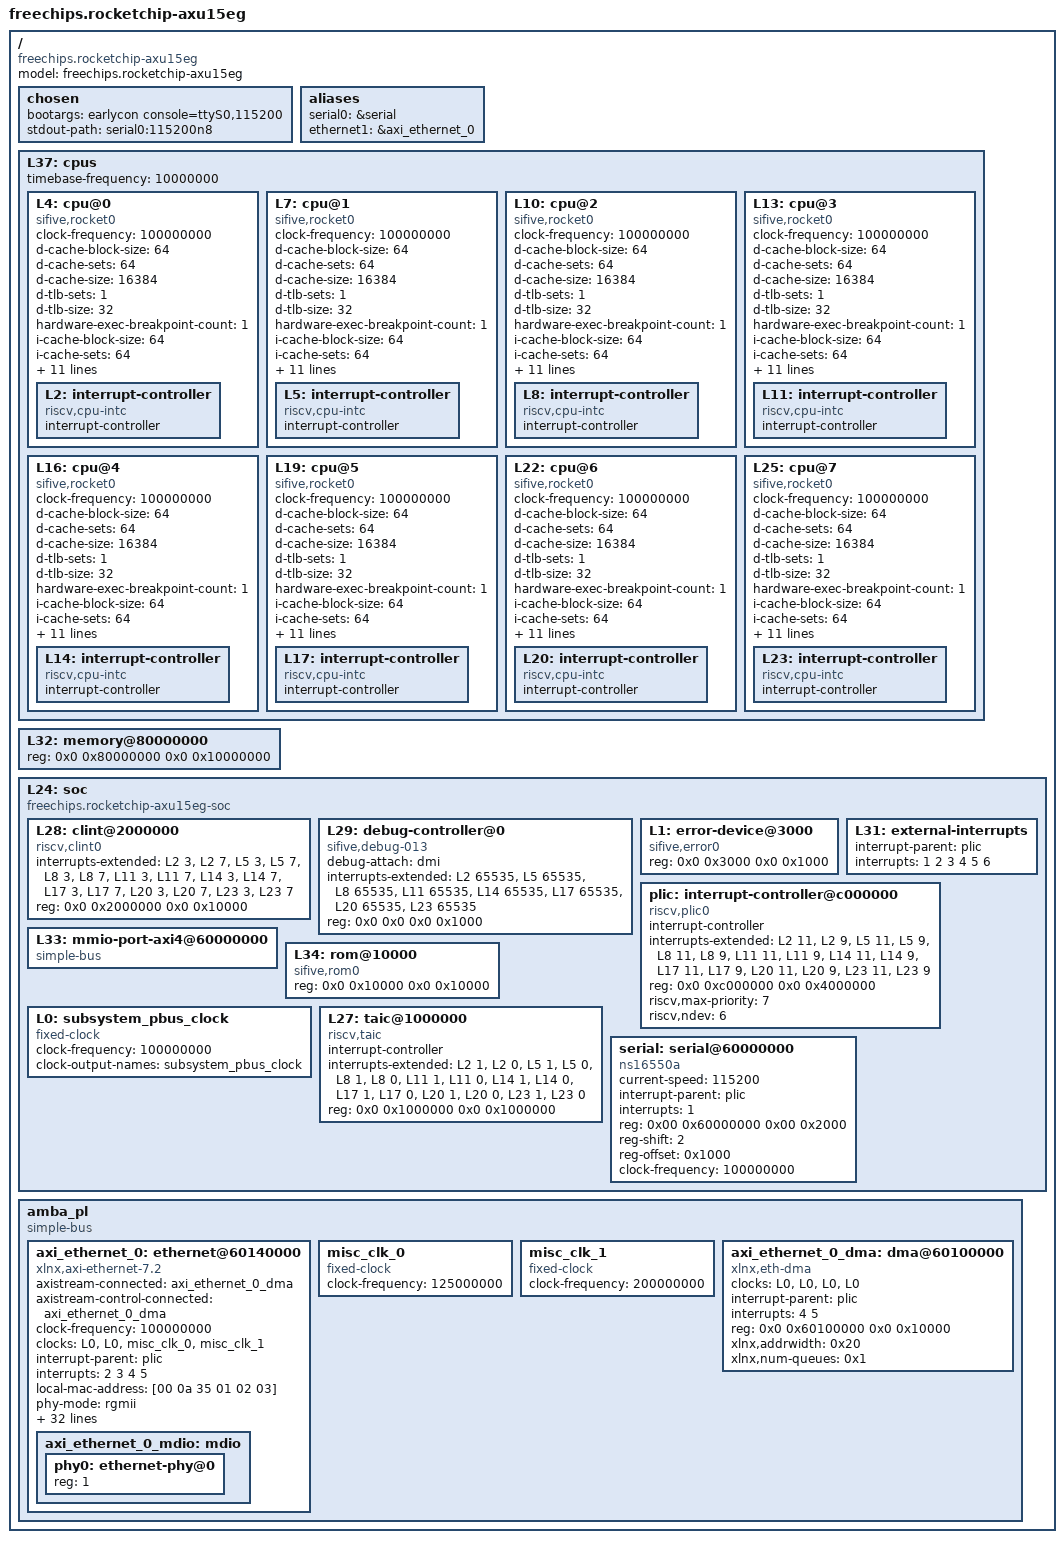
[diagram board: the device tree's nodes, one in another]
/dts-v1/;

/ {
        #address-cells = <2>;
        #size-cells = <2>;
        compatible = "freechips.rocketchip-axu15eg";
        model = "freechips.rocketchip-axu15eg";

        chosen {
            bootargs = "earlycon console=ttyS0,115200";
            stdout-path = "serial0:115200n8";
        };

        aliases {
            serial0 = &serial;
            ethernet1 = &axi_ethernet_0;
        };

        L37: cpus {
                #address-cells = <1>;
                #size-cells = <0>;
                timebase-frequency = <10000000>;
                L4: cpu@0 {
                        clock-frequency = <100000000>;
                        compatible = "sifive,rocket0", "riscv";
                        d-cache-block-size = <64>;
                        d-cache-sets = <64>;
                        d-cache-size = <16384>;
                        d-tlb-sets = <1>;
                        d-tlb-size = <32>;
                        device_type = "cpu";
                        hardware-exec-breakpoint-count = <1>;
                        i-cache-block-size = <64>;
                        i-cache-sets = <64>;
                        i-cache-size = <16384>;
                        i-tlb-sets = <1>;
                        i-tlb-size = <32>;
                        mmu-type = "riscv,sv39";
                        next-level-cache = <&L32>;
                        reg = <0x0>;
                        riscv,isa = "rv64imafdc";
                        riscv,pmpgranularity = <4>;
                        riscv,pmpregions = <8>;
                        status = "okay";
                        timebase-frequency = <10000000>;
                        tlb-split;
                        L2: interrupt-controller {
                                #address-cells = <1>;
                                #interrupt-cells = <1>;
                                compatible = "riscv,cpu-intc";
                                interrupt-controller;
                        };
                };
                L7: cpu@1 {
                        clock-frequency = <100000000>;
                        compatible = "sifive,rocket0", "riscv";
                        d-cache-block-size = <64>;
                        d-cache-sets = <64>;
                        d-cache-size = <16384>;
                        d-tlb-sets = <1>;
                        d-tlb-size = <32>;
                        device_type = "cpu";
                        hardware-exec-breakpoint-count = <1>;
                        i-cache-block-size = <64>;
                        i-cache-sets = <64>;
                        i-cache-size = <16384>;
                        i-tlb-sets = <1>;
                        i-tlb-size = <32>;
                        mmu-type = "riscv,sv39";
                        next-level-cache = <&L32>;
                        reg = <0x1>;
                        riscv,isa = "rv64imafdc";
                        riscv,pmpgranularity = <4>;
                        riscv,pmpregions = <8>;
                        status = "okay";
                        timebase-frequency = <10000000>;
                        tlb-split;
                        L5: interrupt-controller {
                                #address-cells = <1>;
                                #interrupt-cells = <1>;
                                compatible = "riscv,cpu-intc";
                                interrupt-controller;
                        };
                };
                L10: cpu@2 {
                        clock-frequency = <100000000>;
                        compatible = "sifive,rocket0", "riscv";
                        d-cache-block-size = <64>;
                        d-cache-sets = <64>;
                        d-cache-size = <16384>;
                        d-tlb-sets = <1>;
                        d-tlb-size = <32>;
                        device_type = "cpu";
                        hardware-exec-breakpoint-count = <1>;
                        i-cache-block-size = <64>;
                        i-cache-sets = <64>;
                        i-cache-size = <16384>;
                        i-tlb-sets = <1>;
                        i-tlb-size = <32>;
                        mmu-type = "riscv,sv39";
                        next-level-cache = <&L32>;
                        reg = <0x2>;
                        riscv,isa = "rv64imafdc";
                        riscv,pmpgranularity = <4>;
                        riscv,pmpregions = <8>;
                        status = "okay";
                        timebase-frequency = <10000000>;
                        tlb-split;
                        L8: interrupt-controller {
                                #address-cells = <1>;
                                #interrupt-cells = <1>;
                                compatible = "riscv,cpu-intc";
                                interrupt-controller;
                        };
                };
                L13: cpu@3 {
                        clock-frequency = <100000000>;
                        compatible = "sifive,rocket0", "riscv";
                        d-cache-block-size = <64>;
                        d-cache-sets = <64>;
                        d-cache-size = <16384>;
                        d-tlb-sets = <1>;
                        d-tlb-size = <32>;
                        device_type = "cpu";
                        hardware-exec-breakpoint-count = <1>;
                        i-cache-block-size = <64>;
                        i-cache-sets = <64>;
                        i-cache-size = <16384>;
                        i-tlb-sets = <1>;
                        i-tlb-size = <32>;
                        mmu-type = "riscv,sv39";
                        next-level-cache = <&L32>;
                        reg = <0x3>;
                        riscv,isa = "rv64imafdc";
                        riscv,pmpgranularity = <4>;
                        riscv,pmpregions = <8>;
                        status = "okay";
                        timebase-frequency = <10000000>;
                        tlb-split;
                        L11: interrupt-controller {
                                #address-cells = <1>;
                                #interrupt-cells = <1>;
                                compatible = "riscv,cpu-intc";
                                interrupt-controller;
                        };
                };
                L16: cpu@4 {
                        clock-frequency = <100000000>;
                        compatible = "sifive,rocket0", "riscv";
                        d-cache-block-size = <64>;
                        d-cache-sets = <64>;
                        d-cache-size = <16384>;
                        d-tlb-sets = <1>;
                        d-tlb-size = <32>;
                        device_type = "cpu";
                        hardware-exec-breakpoint-count = <1>;
                        i-cache-block-size = <64>;
                        i-cache-sets = <64>;
                        i-cache-size = <16384>;
                        i-tlb-sets = <1>;
                        i-tlb-size = <32>;
                        mmu-type = "riscv,sv39";
                        next-level-cache = <&L32>;
                        reg = <0x4>;
                        riscv,isa = "rv64imafdc";
                        riscv,pmpgranularity = <4>;
                        riscv,pmpregions = <8>;
                        status = "okay";
                        timebase-frequency = <10000000>;
                        tlb-split;
                        L14: interrupt-controller {
                                #address-cells = <1>;
                                #interrupt-cells = <1>;
                                compatible = "riscv,cpu-intc";
                                interrupt-controller;
                        };
                };
                L19: cpu@5 {
                        clock-frequency = <100000000>;
                        compatible = "sifive,rocket0", "riscv";
                        d-cache-block-size = <64>;
                        d-cache-sets = <64>;
                        d-cache-size = <16384>;
                        d-tlb-sets = <1>;
                        d-tlb-size = <32>;
                        device_type = "cpu";
                        hardware-exec-breakpoint-count = <1>;
                        i-cache-block-size = <64>;
                        i-cache-sets = <64>;
                        i-cache-size = <16384>;
                        i-tlb-sets = <1>;
                        i-tlb-size = <32>;
                        mmu-type = "riscv,sv39";
                        next-level-cache = <&L32>;
                        reg = <0x5>;
                        riscv,isa = "rv64imafdc";
                        riscv,pmpgranularity = <4>;
                        riscv,pmpregions = <8>;
                        status = "okay";
                        timebase-frequency = <10000000>;
                        tlb-split;
                        L17: interrupt-controller {
                                #address-cells = <1>;
                                #interrupt-cells = <1>;
                                compatible = "riscv,cpu-intc";
                                interrupt-controller;
                        };
                };
                L22: cpu@6 {
                        clock-frequency = <100000000>;
                        compatible = "sifive,rocket0", "riscv";
                        d-cache-block-size = <64>;
                        d-cache-sets = <64>;
                        d-cache-size = <16384>;
                        d-tlb-sets = <1>;
                        d-tlb-size = <32>;
                        device_type = "cpu";
                        hardware-exec-breakpoint-count = <1>;
                        i-cache-block-size = <64>;
                        i-cache-sets = <64>;
                        i-cache-size = <16384>;
                        i-tlb-sets = <1>;
                        i-tlb-size = <32>;
                        mmu-type = "riscv,sv39";
                        next-level-cache = <&L32>;
                        reg = <0x6>;
                        riscv,isa = "rv64imafdc";
                        riscv,pmpgranularity = <4>;
                        riscv,pmpregions = <8>;
                        status = "okay";
                        timebase-frequency = <10000000>;
                        tlb-split;
                        L20: interrupt-controller {
                                #address-cells = <1>;
                                #interrupt-cells = <1>;
                                compatible = "riscv,cpu-intc";
                                interrupt-controller;
                        };
                };
                L25: cpu@7 {
                        clock-frequency = <100000000>;
                        compatible = "sifive,rocket0", "riscv";
                        d-cache-block-size = <64>;
                        d-cache-sets = <64>;
                        d-cache-size = <16384>;
                        d-tlb-sets = <1>;
                        d-tlb-size = <32>;
                        device_type = "cpu";
                        hardware-exec-breakpoint-count = <1>;
                        i-cache-block-size = <64>;
                        i-cache-sets = <64>;
                        i-cache-size = <16384>;
                        i-tlb-sets = <1>;
                        i-tlb-size = <32>;
                        mmu-type = "riscv,sv39";
                        next-level-cache = <&L32>;
                        reg = <0x7>;
                        riscv,isa = "rv64imafdc";
                        riscv,pmpgranularity = <4>;
                        riscv,pmpregions = <8>;
                        status = "okay";
                        timebase-frequency = <10000000>;
                        tlb-split;
                        L23: interrupt-controller {
                                #address-cells = <1>;
                                #interrupt-cells = <1>;
                                compatible = "riscv,cpu-intc";
                                interrupt-controller;
                        };
                };
        };
        L32: memory@80000000 {
                device_type = "memory";
                reg = <0x0 0x80000000 0x0 0x10000000>;
        };
        L24: soc {
                #address-cells = <2>;
                #size-cells = <2>;
                compatible = "freechips.rocketchip-axu15eg-soc", "simple-bus";
                ranges;
                L28: clint@2000000 {
                        compatible = "riscv,clint0";
                        interrupts-extended = <&L2 3 &L2 7 &L5 3 &L5 7 &L8 3 &L8 7 &L11 3 &L11 7 &L14 3 &L14 7 &L17 3 &L17 7 &L20 3 &L20 7 &L23 3 &L23 7>;
                        reg = <0x0 0x2000000 0x0 0x10000>;
                        reg-names = "control";
                };
                L29: debug-controller@0 {
                        compatible = "sifive,debug-013", "riscv,debug-013";
                        debug-attach = "dmi";
                        interrupts-extended = <&L2 65535 &L5 65535 &L8 65535 &L11 65535 &L14 65535 &L17 65535 &L20 65535 &L23 65535>;
                        reg = <0x0 0x0 0x0 0x1000>;
                        reg-names = "control";
                };
                L1: error-device@3000 {
                        compatible = "sifive,error0";
                        reg = <0x0 0x3000 0x0 0x1000>;
                };
                L31: external-interrupts {
                        interrupt-parent = <&plic>;
                        interrupts = <1 2 3 4 5 6>;
                };
                plic: interrupt-controller@c000000 {
                        #address-cells = <2>;
                        #size-cells = <2>;
                        #interrupt-cells = <1>;
                        compatible = "riscv,plic0";
                        interrupt-controller;
                        interrupts-extended = <&L2 11 &L2 9 &L5 11 &L5 9 &L8 11 &L8 9 &L11 11 &L11 9 &L14 11 &L14 9 &L17 11 &L17 9 &L20 11 &L20 9 &L23 11 &L23 9>;
                        reg = <0x0 0xc000000 0x0 0x4000000>;
                        reg-names = "control";
                        riscv,max-priority = <7>;
                        riscv,ndev = <6>;
                };
                L33: mmio-port-axi4@60000000 {
			#address-cells = <1>;
			#size-cells = <1>;
			compatible = "simple-bus";
			ranges = <0x60000000 0x0 0x60000000 0x20000000>;
		};
                L34: rom@10000 {
                        compatible = "sifive,rom0";
                        reg = <0x0 0x10000 0x0 0x10000>;
                        reg-names = "mem";
                };
                L0: subsystem_pbus_clock {
                        #clock-cells = <0>;
                        clock-frequency = <100000000>;
                        clock-output-names = "subsystem_pbus_clock";
                        compatible = "fixed-clock";
                };
                L27: taic@1000000 {
                        #address-cells = <2>;
                        #interrupt-cells = <1>;
                        compatible = "riscv,taic";
                        interrupt-controller;
                        interrupts-extended = <&L2 1 &L2 0 &L5 1 &L5 0 &L8 1 &L8 0 &L11 1 &L11 0 &L14 1 &L14 0 &L17 1 &L17 0 &L20 1 &L20 0 &L23 1 &L23 0>;
                        reg = <0x0 0x1000000 0x0 0x1000000>;
                        reg-names = "control";
                };
                serial: serial@60000000 {
                    compatible = "ns16550a";
                    current-speed = <115200>;
                    interrupt-parent = <&plic>;
                    interrupts = <1>;
                    reg = <0x00 0x60000000 0x00 0x2000>;
                    reg-shift = <2>;
                    reg-offset = <0x1000>;
                    clock-frequency = <100000000>;
                };
        };

        amba_pl: amba_pl {
            #address-cells = <2>;
            #size-cells = <2>;
            compatible = "simple-bus";
            ranges ;
            axi_ethernet_0: ethernet@60140000 {
                axistream-connected = <&axi_ethernet_0_dma>;
                axistream-control-connected = <&axi_ethernet_0_dma>;
                clock-frequency = <100000000>;
                clock-names = "s_axi_lite_clk", "axis_clk", "gtx_clk", "ref_clk";
                clocks = <&L0>, <&L0>, <&misc_clk_0>, <&misc_clk_1>;
                compatible = "xlnx,axi-ethernet-7.2", "xlnx,axi-ethernet-1.00.a";
                device_type = "network";
                interrupt-names = "mac_irq", "interrupt", "mm2s_introut", "s2mm_introut";
                interrupt-parent = <&plic>;
                interrupts = <2 3 4 5>;
                local-mac-address = [00 0a 35 01 02 03];
                phy-mode = "rgmii";
                reg = <0x0 0x60140000 0x0 0x10000>;
                xlnx = <0x0>;
                xlnx,axiliteclkrate = <0x0>;
                xlnx,axisclkrate = <0x0>;
                xlnx,channel-ids = "1";
                xlnx,clockselection = <0x0>;
                xlnx,enableasyncsgmii = <0x0>;
                xlnx,gt-type = <0x0>;
                xlnx,gtinex = <0x0>;
                xlnx,gtlocation = <0x0>;
                xlnx,gtrefclksrc = <0x0>;
                xlnx,instantiatebitslice0 = <0x0>;
                xlnx,num-queues = /bits/ 16 <0x1>;
                xlnx,phy-type = <0x3>;
                xlnx,phyaddr = <0x1>;
                xlnx,phyrst-board-interface-dummy-port = <0x0>;
                xlnx,rable = <0x0>;
                xlnx,rxcsum = <0x0>;
                xlnx,rxlane0-placement = <0x0>;
                xlnx,rxlane1-placement = <0x0>;
                xlnx,rxmem = <0x8000>;
                xlnx,txmem = <0x8000>;
                xlnx,rxnibblebitslice0used = <0x0>;
                xlnx,tx-in-upper-nibble = <0x1>;
                xlnx,txcsum = <0x0>;
                xlnx,txlane0-placement = <0x0>;
                xlnx,txlane1-placement = <0x0>;
                xlnx,versal-gt-board-flow = <0x0>;
                max-speed = <1000>;
                zclock-names = "NULL";
                zclocks = "NULL";
                phy-handle = <&phy0>;
                axi_ethernet_0_mdio: mdio {
                    #address-cells = <1>;
                    #size-cells = <0>;
                    phy0: ethernet-phy@0 {
                        device_type = "ethernet-phy";
                        reg = <1>;
                    };
                };
            };
            misc_clk_0: misc_clk_0 {
                #size-cells = <0>;
                #clock-cells = <0>;
                clock-frequency = <125000000>;
                compatible = "fixed-clock";
            };
            misc_clk_1: misc_clk_1 {
                #size-cells = <0>;
                #clock-cells = <0>;
                clock-frequency = <200000000>;
                compatible = "fixed-clock";
            };
            axi_ethernet_0_dma: dma@60100000 {
                #dma-cells = <1>;
                clock-names = "s_axi_lite_aclk", "m_axi_sg_aclk", "m_axi_mm2s_aclk", "m_axi_s2mm_aclk";
                clocks = <&L0>, <&L0>, <&L0>, <&L0>;
                compatible = "xlnx,eth-dma";
                interrupt-names = "mm2s_introut", "s2mm_introut";
                interrupt-parent = <&plic>;
                interrupts = <4 5>;
                reg = <0x0 0x60100000 0x0 0x10000>;
                xlnx,addrwidth = /bits/ 8 <0x20>;
                xlnx,num-queues = /bits/ 16 <0x1>;
            };
        };
};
